# PY32T020xx register map
Vendor: Puya; Series: PY32L0; File version: 1.0.0
CPU: CM0+ r0p1, little endian, no MPU, no FPU, 4 interrupt priority bits
Registers are 32-bit, read-write, reset 0x0 unless marked. A register's access mark holds for its fields unless they carry their own. Offsets are from the block's base; [hi:lo] are bit positions.

## LPTIM1 — Low power timer
Base 0x40007C00
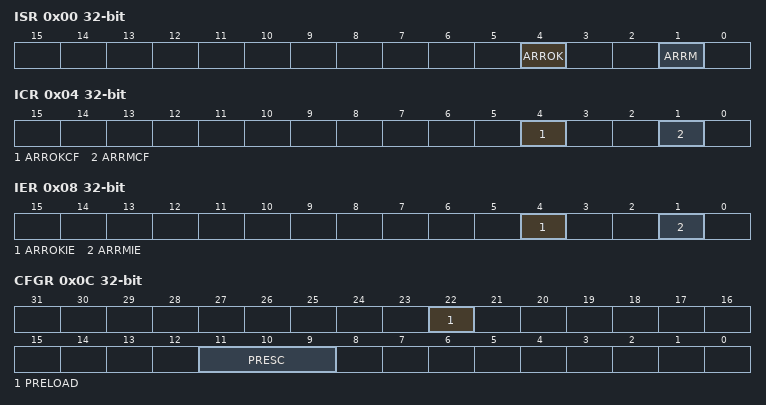
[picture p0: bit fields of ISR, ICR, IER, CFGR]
0x00 ISR ro — Interrupt and Status Register
  [4] ARROK — Autoreload match update OK
  [1] ARRM — Autoreload match
0x04 ICR wo — Interrupt Clear Register
  [4] ARROKCF — Autoreload match update OK Clear Flag
  [1] ARRMCF — Autoreload match Clear Flag
0x08 IER — Interrupt Enable Register
  [4] ARROKIE — Autoreload match update OK Interrupt Enable
  [1] ARRMIE — Autoreload matchInterrupt Enable
0x0C CFGR — Configuration Register
  [22] PRELOAD — Registers update mode
  [11:9] PRESC — Clock prescaler
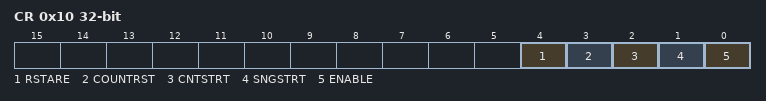
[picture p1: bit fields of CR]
0x10 CR — Control Register
  [4] RSTARE — Reset after read enable
  [3] COUNTRST — Reset counter
  [2] CNTSTRT
  [1] SNGSTRT — LPTIM start in single mode
  [0] ENABLE — LPTIM Enable
0x18 ARR reset 0x1 — Autoreload Register
  [15:0] ARR — Auto reload value
0x1C CNT ro — Counter Register
  [15:0] CNT — Counter value

## PWR — Power control
Base 0x40007000
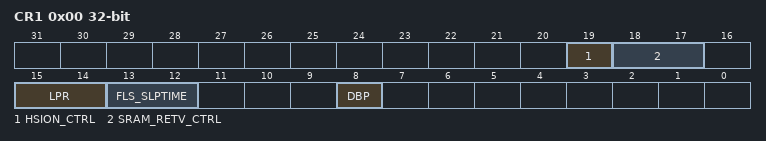
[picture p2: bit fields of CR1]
0x00 CR1 — Power control register 1
  [19] HSION_CTRL
  [18:17] SRAM_RETV_CTRL — sram retev control
    1=0; 2=1
  [15:14] LPR — pmu mode control
    1=0; 2=1
  [13:12] FLS_SLPTIME — flash sleep time control
    1=0; 2=1
  [8] DBP — dbg mode protect enable

## RTC — Real time clock
Base 0x40002800
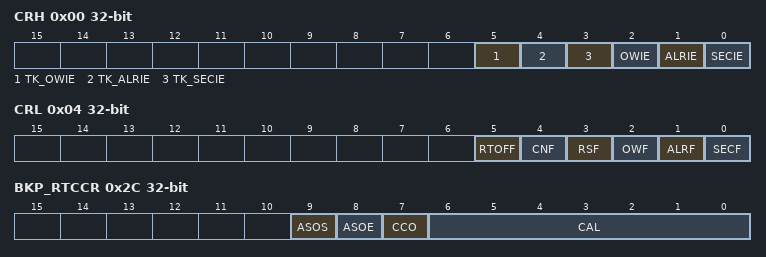
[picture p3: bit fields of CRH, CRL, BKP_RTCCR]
0x00 CRH — RTC Control Register High
  [5] TK_OWIE — TK overflow interrupt allowable bits
  [4] TK_ALRIE — TK alarm interrupt allowed bits
  [3] TK_SECIE — TK sec interrupt allowable bits
  [2] OWIE — Overflow interrupt allow bits
  [1] ALRIE — Alarm interrupt allowed bits
  [0] SECIE — Seconds interrupt allowed bits
0x04 CRL — RTC Control Register Low
  [5] RTOFF ro — RTC operation OFF
  [4] CNF — Configuration flag
  [3] RSF — Registers synchronized flag
  [2] OWF — Overflow flag
  [1] ALRF — Alarm flag
  [0] SECF — Second flag
0x08 PRLH — RTC Prescaler Load Register High
  [5:0] PRL wo — RTC prescaler reload value high
0x0C PRLL — RTC Prescaler Load Register Low
  [15:0] PRL wo — RTC prescaler reload value high
0x10 DIVH — RTC Prescaler Divider Register High
  [3:0] RTC_DIV ro — RTC clock divider
0x14 DIVL — RTC Prescaler Divider Register Low
  [15:0] RTC_DIV ro — RTC clock divider
0x18 CNTH — RTC Counter Register High
  [15:0] RTC_CNT — RTC core counter
0x1C CNTL — RTC Counter Register Low
  [15:0] RTC_CNT — RTC core counter
0x20 ALRH — RTC Alarm Register High
  [15:0] ALR — RTC alarm value
0x24 ALRL — RTC Alarm Register Low
  [15:0] ALR — RTC alarm value
0x2C BKP_RTCCR
  [9] ASOS — Seconds/alarm pulse output select bits
  [8] ASOE — Seconds/alarm pulse output enable bit
  [7] CCO — Calibrate the clock output bits
  [6:0] CAL — Calibration value

## SPI1 — Serial peripheral interface
Base 0x40013000
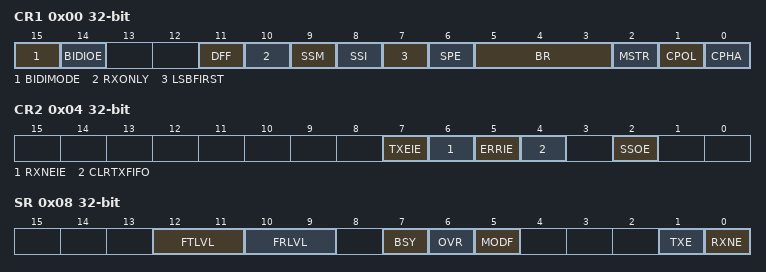
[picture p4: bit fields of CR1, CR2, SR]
0x00 CR1
  [15] BIDIMODE — Bidirectional data mode enable
  [14] BIDIOE — Output enable in bidirectional mode
  [11] DFF — Data frame format
  [10] RXONLY — Receive only
  [9] SSM — Software slave management
  [8] SSI — Internal slave select
  [7] LSBFIRST — Frame Format
  [6] SPE — SPI Enable
  [5:3] BR — Baud Rate Control
    1=0; 2=1; 4=2
  [2] MSTR — Master Selection
  [1] CPOL — Clock Polarity
  [0] CPHA — Clock Phase
0x04 CR2
  [7] TXEIE — Tx buffer Empty Interrupt Enable
  [6] RXNEIE — RX buffer Not Empty Interrupt Enable
  [5] ERRIE — Error Interrupt Enable
  [4] CLRTXFIFO — Clear FIFO
  [2] SSOE — SS Output Enable
0x08 SR
  [12:11] FTLVL ro — FIFO Transmission Level
    1=0; 2=1
  [10:9] FRLVL ro — FIFO Reception Level
    1=0; 2=1
  [7] BSY ro — Busy flag
  [6] OVR ro — Overrun flag
  [5] MODF — Mode fault
  [1] TXE ro — Transmit buffer Empty
  [0] RXNE ro — Receive buffer Not Empty
0x0C DR
  [15:0] DR — Data Register
